# DMPAC0_PAR_PAR_SDE_S_VBUSP_MEM_MMRRAM_VBUSP_MMR_RAM register map
Vendor: Texas Instruments
Peripheral module from a debugger description file (folder J7ES).
Registers are 32-bit, read-only, reset 0x0 unless marked. A register's access mark holds for its fields unless they carry their own. Offsets are as the file gives them; lines under a group give offsets from that group; [hi:lo] are bit positions; {n}, {i} and the like mark numbered series; 'fields as' and 'values as' point back to an identical list; <NAME> marks a mode.

## DMPAC0_PAR_PAR_SDE_S_VBUSP_MEM_MMRRAM_VBUSP_MMR_RAM
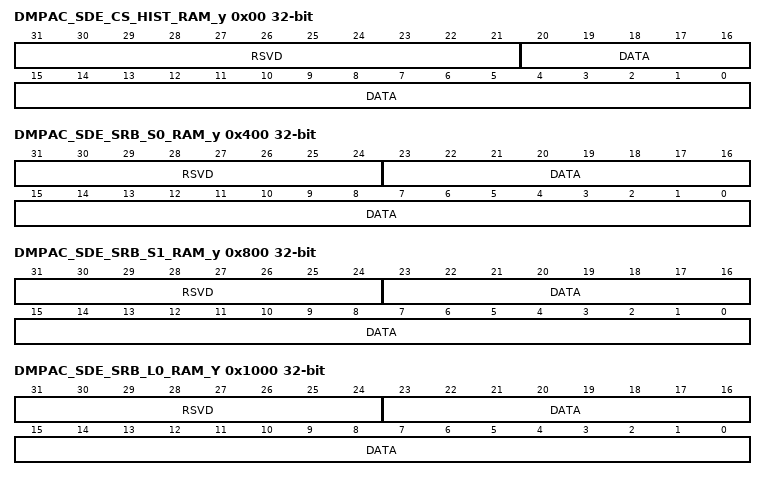
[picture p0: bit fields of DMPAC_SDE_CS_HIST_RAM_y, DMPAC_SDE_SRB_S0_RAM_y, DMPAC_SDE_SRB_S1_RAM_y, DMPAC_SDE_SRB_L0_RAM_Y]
0x00 DMPAC_SDE_CS_HIST_RAM_y — cs_hist_ram diagnostic read only port, vbusp will stall until RAM is available for read Offset = 00140000h + (y * 4h); where y = 0h to 7Fh
  [31:21] RSVD — Always read as 0.Writes have no effect.
  [20:0] DATA — Data read from RAM
0x400 DMPAC_SDE_SRB_S0_RAM_y — srb_s0_ram diagnostic read only port, vbusp will stall until RAM is available for read Offset = 00140400h + (y * 4h); where y = 0h to FFh
  [31:24] RSVD — Always read as 0.Writes have no effect.
  [23:0] DATA — Data read from RAM
0x800 DMPAC_SDE_SRB_S1_RAM_y — srb_s1_ram diagnostic read only port, vbusp will stall until RAM is available for read Offset = 00140800h + (y * 4h); where y = 0h to FFh
  fields as DMPAC_SDE_SRB_S0_RAM_y
0x1000 DMPAC_SDE_SRB_L0_RAM_Y — srb_l0_ram diagnostic read only port, vbusp will stall until RAM is available for read Offset = 00141000h + (y * 4h); where y = 0h to 1FFh
  fields as DMPAC_SDE_SRB_S0_RAM_y
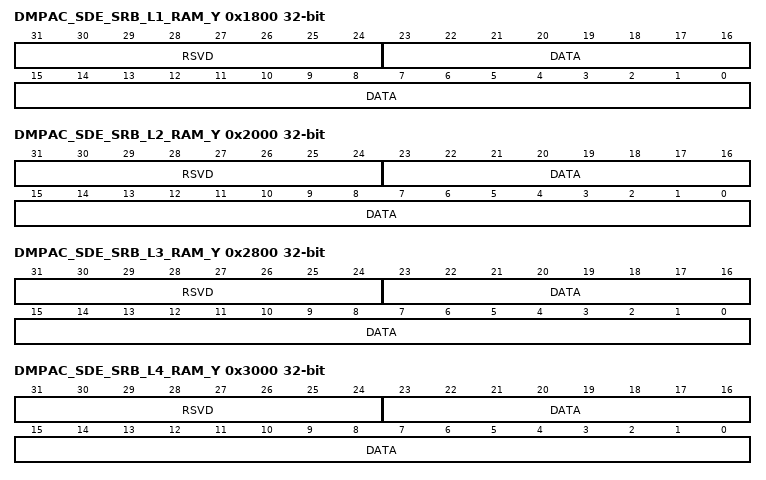
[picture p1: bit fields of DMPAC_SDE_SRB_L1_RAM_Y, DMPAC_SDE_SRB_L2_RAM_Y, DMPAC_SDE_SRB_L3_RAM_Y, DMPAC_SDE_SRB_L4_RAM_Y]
0x1800 DMPAC_SDE_SRB_L1_RAM_Y — srb_l1_ram diagnostic read only port, vbusp will stall until RAM is available for read Offset = 00141800h + (y * 4h); where y = 0h to 1FFh
  fields as DMPAC_SDE_SRB_S0_RAM_y
0x2000 DMPAC_SDE_SRB_L2_RAM_Y — srb_l2_ram diagnostic read only port, vbusp will stall until RAM is available for read Offset = 00142000h + (y * 4h); where y = 0h to 1FFh
  fields as DMPAC_SDE_SRB_S0_RAM_y
0x2800 DMPAC_SDE_SRB_L3_RAM_Y — srb_l3_ram diagnostic read only port, vbusp will stall until RAM is available for read Offset = 00142800h + (y * 4h); where y = 0h to 1FFh
  fields as DMPAC_SDE_SRB_S0_RAM_y
0x3000 DMPAC_SDE_SRB_L4_RAM_Y — srb_l4_ram diagnostic read only port, vbusp will stall until RAM is available for read Offset = 00143000h + (y * 4h); where y = 0h to 1FFh
  fields as DMPAC_SDE_SRB_S0_RAM_y
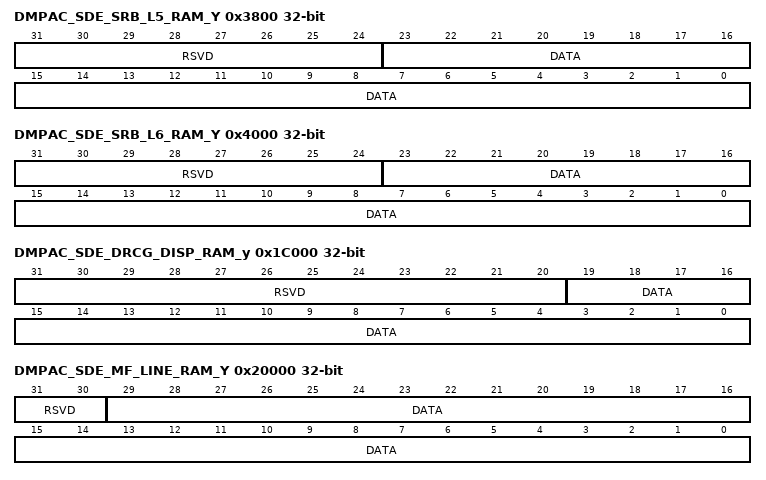
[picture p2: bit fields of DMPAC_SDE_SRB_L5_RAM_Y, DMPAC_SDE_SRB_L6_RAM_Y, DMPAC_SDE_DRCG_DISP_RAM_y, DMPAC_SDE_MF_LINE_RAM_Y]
0x3800 DMPAC_SDE_SRB_L5_RAM_Y — srb_l5_ram diagnostic read only port, vbusp will stall until RAM is available for read Offset = 00143800h + (y * 4h); where y = 0h to 1FFh
  fields as DMPAC_SDE_SRB_S0_RAM_y
0x4000 DMPAC_SDE_SRB_L6_RAM_Y — srb_l6_ram diagnostic read only port, vbusp will stall until RAM is available for read Offset = 00144000h + (y * 4h); where y = 0h to 1FFh
  fields as DMPAC_SDE_SRB_S0_RAM_y
0x6000 DMPAC_SDE_DRCG_FAST_LR_RAM_Y — drcg_fast_lr_ram diagnostic read only port, vbusp will stall until RAM is available for read Offset = 00146000h + (y * 4h); where y = 0h to 5FFh
  [31:0] DATA — Data read from RAM.RAM is wider than 32bit vbus. MMR reads are byte addresses into RAM where RAM Width is extended/zero padded to next pwr2.
0x8000 DMPAC_SDE_LCC_OP0_RAM_y — lcc_op0_ram diagnostic read only port, vbusp will stall until RAM is available for read Offset = 00148000h + (y * 4h); where y = 0h to 9FFh
  fields as DMPAC_SDE_DRCG_FAST_LR_RAM_Y
0xC000 DMPAC_SDE_LCC_OP1_RAM_y — lcc_op1_ram diagnostic read only port, vbusp will stall until RAM is available for read Offset = 0014C000h + (y * 4h); where y = 0h to 9FFh
  fields as DMPAC_SDE_DRCG_FAST_LR_RAM_Y
{0x8000+0x4000*i} DMPAC_SDE_LCC_OP{i}_RAM_y (i=2..4) — lcc_op{i}_ram diagnostic read only port, vbusp will stall until RAM is available for read Offset = {4000i+142000:08}h + (y * 4h); where y = 0h to 9FFh
  fields as DMPAC_SDE_DRCG_FAST_LR_RAM_Y
0x1C000 DMPAC_SDE_DRCG_DISP_RAM_y — drcg_disp_ram diagnostic read only port, vbusp will stall until RAM is available for read Offset = 0015C000h + (y * 4h); where y = 0h to BFFh
  [31:20] RSVD — Always read as 0.Writes have no effect.
  [19:0] DATA — Data read from RAM
0x20000 DMPAC_SDE_MF_LINE_RAM_Y — mf_line_ram diagnostic read only port, vbusp will stall until RAM is available for read Offset = 00160000h + (y * 4h); where y = 0h to FFFh
  [31:30] RSVD — Always read as 0.Writes have no effect.
  [29:0] DATA — Data read from RAM
0x28000 DMPAC_SDE_SCA_BRC_RAM_y — sca_brc_ram diagnostic read only port, vbusp will stall until RAM is available for read Offset = 00168000h + (y * 4h); where y = 0h to 1FFFh
  fields as DMPAC_SDE_DRCG_FAST_LR_RAM_Y
0x30000 DMPAC_SDE_SCA_BPCC_RAM_y — sca_bpcc_ram diagnostic read only port, vbusp will stall until RAM is available for read Offset = 00170000h + (y * 4h); where y = 0h to 27FFh
  fields as DMPAC_SDE_DRCG_FAST_LR_RAM_Y
